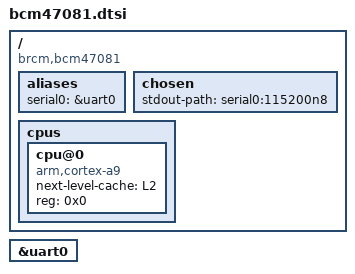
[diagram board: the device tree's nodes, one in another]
/*
 * Broadcom BCM470X / BCM5301X ARM platform code.
 * DTS for BCM47081 SoC.
 *
 * Copyright © 2014 Rafał Miłecki <zajec5@gmail.com>
 *
 * Permission to use, copy, modify, and/or distribute this software for any
 * purpose with or without fee is hereby granted, provided that the above
 * copyright notice and this permission notice appear in all copies.
 *
 * THE SOFTWARE IS PROVIDED "AS IS" AND THE AUTHOR DISCLAIMS ALL WARRANTIES WITH
 * REGARD TO THIS SOFTWARE INCLUDING ALL IMPLIED WARRANTIES OF MERCHANTABILITY
 * AND FITNESS. IN NO EVENT SHALL THE AUTHOR BE LIABLE FOR ANY SPECIAL, DIRECT,
 * INDIRECT, OR CONSEQUENTIAL DAMAGES OR ANY DAMAGES WHATSOEVER RESULTING FROM
 * LOSS OF USE, DATA OR PROFITS, WHETHER IN AN ACTION OF CONTRACT, NEGLIGENCE
 * OR OTHER TORTIOUS ACTION, ARISING OUT OF OR IN CONNECTION WITH THE USE OR
 * PERFORMANCE OF THIS SOFTWARE.
 */

#include "bcm5301x.dtsi"

/ {
	compatible = "brcm,bcm47081";

	aliases {
		serial0 = &uart0;
	};

	chosen {
		stdout-path = "serial0:115200n8";
	};

	cpus {
		#address-cells = <1>;
		#size-cells = <0>;

		cpu@0 {
			device_type = "cpu";
			compatible = "arm,cortex-a9";
			next-level-cache = <&L2>;
			reg = <0x0>;
		};
	};
};

&uart0 {
	status = "okay";
};
